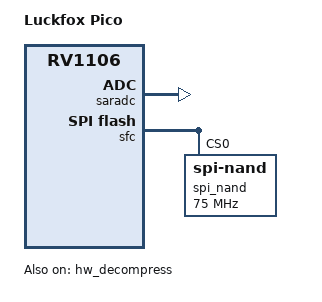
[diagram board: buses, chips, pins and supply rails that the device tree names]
// SPDX-License-Identifier: (GPL-2.0+ OR MIT)
/*
 * Copyright (c) 2022 Rockchip Electronics Co., Ltd.
 */

/dts-v1/;

#include "rv1106.dtsi"
#include <dt-bindings/input/input.h>

/ {
	model = "Luckfox Pico";
	compatible = "rockchip,rv1103g-38x38-ipc-v10", "rockchip,rv1106";

	chosen {
		stdout-path = &uart2;
	};
};

&hw_decompress {
	status = "okay";
};

&saradc {
	status = "okay";
};

&sfc {
	status = "okay";

	spi_nand: flash@0 {
		compatible = "spi-nand";
		reg = <0>;
		spi-max-frequency = <75000000>;
		spi-rx-bus-width = <4>;
		spi-tx-bus-width = <1>;
	};
};
